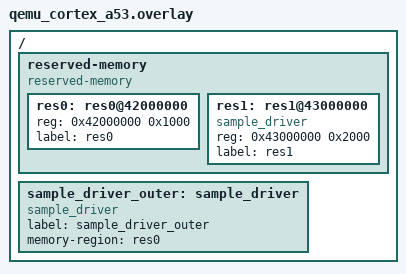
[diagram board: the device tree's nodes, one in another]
/*
 * Copyright (c) 2021 Carlo Caione <ccaione@baylibre.com>
 *
 * SPDX-License-Identifier: Apache-2.0
 */

/ {
	reserved-memory {
		compatible = "reserved-memory";
		#address-cells = <1>;
		#size-cells = <1>;
		status = "okay";
		ranges;

		res0: res0@42000000 {
			reg = <0x42000000 0x1000>;
			label = "res0";
		};

		res1: res1@43000000 {
			reg = <0x43000000 0x2000>;
			compatible = "sample_driver";
			label = "res1";
		};
	};


	sample_driver_outer: sample_driver {
		compatible = "sample_driver";
		label = "sample_driver_outer";
		memory-region = <&res0>;
	};
};
